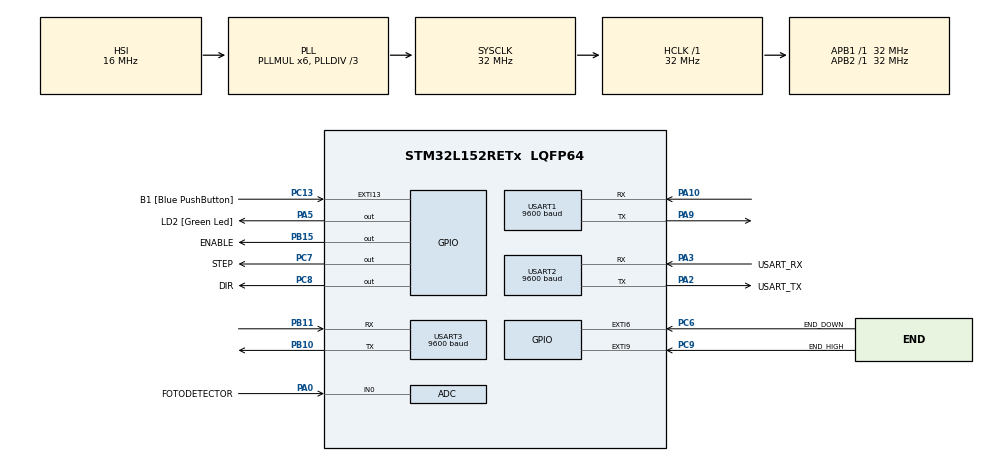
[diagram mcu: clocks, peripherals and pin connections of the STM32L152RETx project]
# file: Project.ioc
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ADC.Channel-0\#ChannelRegularConversion=ADC_CHANNEL_0
ADC.NbrOfConversionFlag=1
ADC.Rank-0\#ChannelRegularConversion=1
ADC.Resolution=ADC_RESOLUTION_8B
ADC.SamplingTime-0\#ChannelRegularConversion=ADC_SAMPLETIME_4CYCLES
ADC.ScanConvMode=ADC_SCAN_ENABLE
Mcu.Family=STM32L1
Mcu.Name=STM32L152RETx
Mcu.Package=LQFP64
NVIC.ADC1_IRQn=true\:0\:0\:false\:false\:true\:true\:true
NVIC.EXTI15_10_IRQn=true\:0\:0\:false\:false\:true\:true\:true
NVIC.EXTI9_5_IRQn=true\:0\:0\:false\:false\:true\:true\:true
NVIC.PriorityGroup=NVIC_PRIORITYGROUP_0
NVIC.USART1_IRQn=true\:0\:0\:false\:false\:true\:true\:true
NVIC.USART2_IRQn=true\:0\:0\:false\:false\:true\:true\:true
NVIC.USART3_IRQn=true\:0\:0\:false\:false\:true\:true\:true
PA0-WKUP1.GPIO_Label=FOTODETECTOR
PA0-WKUP1.Mode=IN0
PA0-WKUP1.Signal=ADC_IN0
PA10.Mode=Asynchronous
PA10.Signal=USART1_RX
PA13.GPIO_Label=TMS
PA13.Signal=SYS_JTMS-SWDIO
PA14.GPIO_Label=TCK
PA14.Signal=SYS_JTCK-SWCLK
PA2.GPIO_Label=USART_TX
PA2.Mode=Asynchronous
PA2.Signal=USART2_TX
PA3.GPIO_Label=USART_RX
PA3.Mode=Asynchronous
PA3.Signal=USART2_RX
PA5.GPIO_Label=LD2 [Green Led]
PA5.Signal=GPIO_Output
PA9.Mode=Asynchronous
PA9.Signal=USART1_TX
PB10.Mode=Asynchronous
PB10.Signal=USART3_TX
PB11.Mode=Asynchronous
PB11.Signal=USART3_RX
PB15.GPIO_Label=ENABLE
PB15.Signal=GPIO_Output
PB3.GPIO_Label=SWO
PB3.Signal=SYS_JTDO-TRACESWO
PC13-WKUP2.GPIO_Label=B1 [Blue PushButton]
PC13-WKUP2.Signal=GPXTI13
PC14-OSC32_IN.Mode=LSE-External-Oscillator
PC14-OSC32_IN.Signal=RCC_OSC32_IN
PC15-OSC32_OUT.Mode=LSE-External-Oscillator
PC15-OSC32_OUT.Signal=RCC_OSC32_OUT
PC6.GPIO_Label=END_DOWN
PC6.GPIO_ModeDefaultEXTI=GPIO_MODE_IT_FALLING
PC6.Signal=GPXTI6
PC7.GPIO_Label=STEP
PC7.Signal=GPIO_Output
PC8.GPIO_Label=DIR
PC8.Signal=GPIO_Output
PC9.GPIO_Label=END_HIGH
PC9.GPIO_ModeDefaultEXTI=GPIO_MODE_IT_FALLING
PC9.Signal=GPXTI9
PH0-OSC_IN.Mode=HSE-External-Clock-Source
PH0-OSC_IN.Signal=RCC_OSC_IN
PH1-OSC_OUT.Signal=RCC_OSC_OUT
ProjectManager.HeapSize=0x200
ProjectManager.StackSize=0x400
ProjectManager.TargetToolchain=STM32CubeIDE
RCC.48MHZClocksFreq_Value=48000000
RCC.AHBFreq_Value=32000000
RCC.APB1Freq_Value=32000000
RCC.APB1TimFreq_Value=32000000
RCC.APB2Freq_Value=32000000
RCC.APB2TimFreq_Value=32000000
RCC.HCLKFreq_Value=32000000
RCC.HSE_VALUE=8000000
RCC.HSI_VALUE=16000000
RCC.MSI_VALUE=2097000
RCC.PLLDIV=RCC_PLL_DIV3
RCC.PLLMUL=RCC_PLL_MUL6
RCC.RTCClockSelectionVirtual=RCC_RTCCLKSOURCE_LSE
RCC.SYSCLKFreq_VALUE=32000000
RCC.SYSCLKSource=RCC_SYSCLKSOURCE_PLLCLK
RCC.USBOutput=48000000
RCC.VCOOutputFreq_Value=96000000
USART1.BaudRate=9600
USART1.VirtualMode=VM_ASYNC
USART2.BaudRate=9600
USART2.VirtualMode=VM_ASYNC
USART3.BaudRate=9600
USART3.VirtualMode=VM_ASYNC
board=NUCLEO-L152RE

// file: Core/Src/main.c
/* USER CODE BEGIN Header */
/**
  ******************************************************************************
  * @file           : main.c
  * @brief          : Main program body
  ******************************************************************************
  * @attention
  *
  * <h2><center>&copy; Copyright (c) 2020 STMicroelectronics.
  * All rights reserved.</center></h2>
  *
  * This software component is licensed by ST under BSD 3-Clause license,
  * the "License"; You may not use this file except in compliance with the
  * License. You may obtain a copy of the License at:
  *                        opensource.org/licenses/BSD-3-Clause
  *
  ******************************************************************************
  */
/* USER CODE END Header */

#include "main.h"
#include "adc.h"
#include "usart.h"
#include "gpio.h"

void SystemClock_Config(void);

int main(void)
{

  /* MCU Configuration--------------------------------------------------------*/

  /* Reset of all peripherals, Initializes the Flash interface and the Systick. */
  HAL_Init();

  /* Configure the system clock */
  SystemClock_Config();

  /* Initialize all configured peripherals */
  MX_GPIO_Init();
  MX_USART2_UART_Init();
  MX_USART1_UART_Init();
  MX_ADC_Init();
  MX_USART3_UART_Init();
  /* USER CODE BEGIN 2 */
  /**
   * wait for uart command from raspberry
   * huart1 is in exit mode
   */
  HAL_UART_Receive_IT(&huart1, &data, 1);
  /**
   * start adc read
   */
  HAL_ADC_Start(&hadc);
  /**
   * wait for uart command from admin
   * huart2 is in exit mode
   */
  HAL_UART_Receive_IT(&huart3, &able, 1);

  /* USER CODE END 2 */

  /* Infinite loop */
  /* USER CODE BEGIN WHILE */
  while (1)
  {

	 auto_fotodetector(get_value_fotodetector());
	 move_motor();
    /* USER CODE END WHILE */

  }
}

void SystemClock_Config(void)
{
  RCC_OscInitTypeDef RCC_OscInitStruct = {0};
  RCC_ClkInitTypeDef RCC_ClkInitStruct = {0};

  /** Configure the main internal regulator output voltage
  */
  __HAL_PWR_VOLTAGESCALING_CONFIG(PWR_REGULATOR_VOLTAGE_SCALE1);
  /** Initializes the CPU, AHB and APB busses clocks
  */
  RCC_OscInitStruct.OscillatorType = RCC_OSCILLATORTYPE_HSI;
  RCC_OscInitStruct.HSIState = RCC_HSI_ON;
  RCC_OscInitStruct.HSICalibrationValue = RCC_HSICALIBRATION_DEFAULT;
  RCC_OscInitStruct.PLL.PLLState = RCC_PLL_ON;
  RCC_OscInitStruct.PLL.PLLSource = RCC_PLLSOURCE_HSI;
  RCC_OscInitStruct.PLL.PLLMUL = RCC_PLL_MUL6;
  RCC_OscInitStruct.PLL.PLLDIV = RCC_PLL_DIV3;
  if (HAL_RCC_OscConfig(&RCC_OscInitStruct) != HAL_OK)
  {
    Error_Handler();
  }
  /** Initializes the CPU, AHB and APB busses clocks
  */
  RCC_ClkInitStruct.ClockType = RCC_CLOCKTYPE_HCLK|RCC_CLOCKTYPE_SYSCLK
                              |RCC_CLOCKTYPE_PCLK1|RCC_CLOCKTYPE_PCLK2;
  RCC_ClkInitStruct.SYSCLKSource = RCC_SYSCLKSOURCE_PLLCLK;
  RCC_ClkInitStruct.AHBCLKDivider = RCC_SYSCLK_DIV1;
  RCC_ClkInitStruct.APB1CLKDivider = RCC_HCLK_DIV1;
  RCC_ClkInitStruct.APB2CLKDivider = RCC_HCLK_DIV1;

  if (HAL_RCC_ClockConfig(&RCC_ClkInitStruct, FLASH_LATENCY_1) != HAL_OK)
  {
    Error_Handler();
  }
}

/* USER CODE BEGIN 4 */
/**
 * uart take command
 */
void HAL_UART_RxCpltCallback(UART_HandleTypeDef *huart)
{
	/**
	 * raspberry uart
	 */
	if(huart->Instance == USART1)
	{
		new_data(data);
		data = 0;
		HAL_UART_Receive_IT(&huart1, &data, 1);
	}
	/**
	 * admin uart
	*/
	if(huart->Instance == USART3)
	{
		admin_pc(able);
		HAL_UART_Receive_IT(&huart3, &able, 1);
	}

}

/* USER CODE END 4 */

void Error_Handler(void)
{
}

/************************ (C) COPYRIGHT STMicroelectronics *****END OF FILE****/
